# TC37X register map
File version: 1.0.0
CPU: CM4 r0p1, little endian, MPU, FPU, VTOR, 3 interrupt priority bits
Registers are 16-bit, read-write, reset 0x0 unless marked. A register's access mark holds for its fields unless they carry their own. Offsets are from the block's base; [hi:lo] are bit positions; {n}, {i} and the like mark numbered series.

## INT — ce_int
Base 0xF0037000
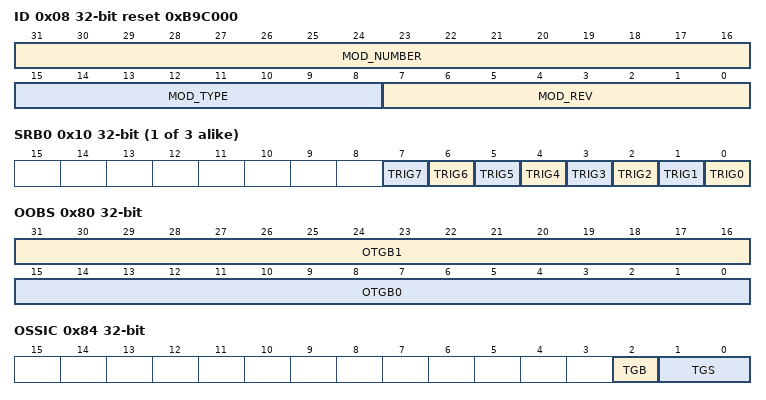
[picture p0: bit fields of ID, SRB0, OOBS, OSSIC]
0x08 ID 32-bit ro reset 0xB9C000 (reset mask 0xFFFFFF00) — Module Identification Register
  [31:16] MOD_NUMBER — Module Number Value
  [15:8] MOD_TYPE — Module Type
  [7:0] MOD_REV — Module Revision Number
{0x10+4i} SRB{i} 32-bit wo (i=0..2) — Service Request Broadcast Register {i}
  [n] TRIG{n} (n=0..7) — General Purpose Service Request Trigger {n}
0x80 OOBS 32-bit ro — OTGM OTGB0/1 Status
  [31:16] OTGB1 — Status of OTGB1
  [15:0] OTGB0 — Status of OTGB0
0x84 OSSIC 32-bit — OTGM SSI Control
  [2] TGB — OTGB0/1 Bus Select
  [1:0] TGS — Trigger Set for OTGB0/1
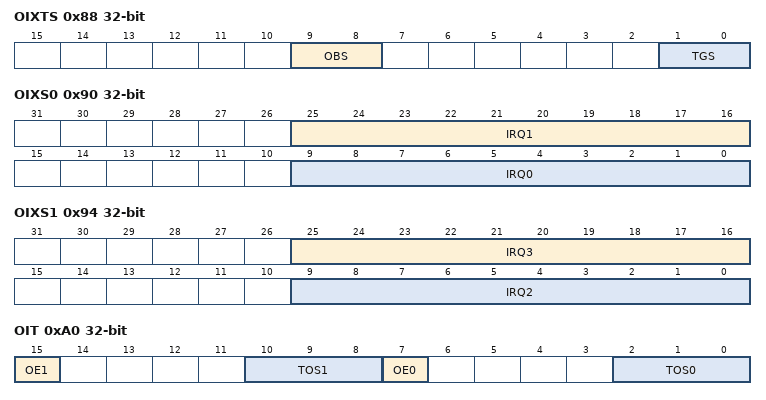
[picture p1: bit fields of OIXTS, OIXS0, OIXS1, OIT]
0x88 OIXTS 32-bit — OTGM IRQ MUX Trigger Set Select
  [9:8] OBS — Overlay Byte Select
  [1:0] TGS — Trigger Set Select for OTGB0/1 Overlay
0x8C OIXMS 32-bit — OTGM IRQ MUX Missed IRQ Select
  [9:0] MIRQ — SRN Index for Missed Interrupt Trigger
0x90 OIXS0 32-bit — OTGM IRQ MUX Select 0
  [25:16] IRQ1 — SRN Index for Interrupt Trigger 1
  [9:0] IRQ0 — SRN Index for Interrupt Trigger 0
0x94 OIXS1 32-bit — OTGM IRQ MUX Select 1
  [25:16] IRQ3 — SRN Index for Interrupt Trigger 3
  [9:0] IRQ2 — SRN Index for Interrupt Trigger 2
0xA0 OIT 32-bit — OTGM IRQ Trace
  [15] OE1 — Output Enable for OTGB1
  [10:8] TOS1 — Type of Service for Observation on OTGB1
  [7] OE0 — Output Enable for OTGB0
  [2:0] TOS0 — Type of Service for Observation on OTGB0
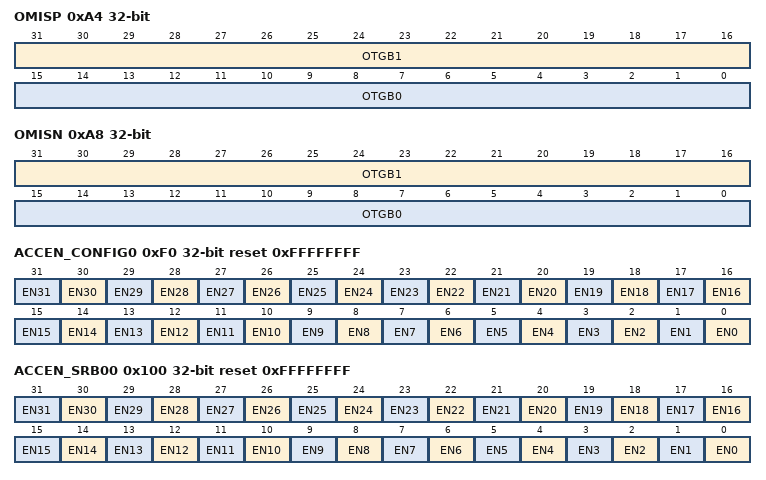
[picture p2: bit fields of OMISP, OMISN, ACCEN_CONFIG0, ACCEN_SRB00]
0xA4 OMISP 32-bit — OTGM MCDS I/F Sensitivity Posedge
  [31:16] OTGB1 — Bitwise Posedge Sensitivity for OTGB1
  [15:0] OTGB0 — Bitwise Posedge Sensitivity for OTGB0
0xA8 OMISN 32-bit — OTGM MCDS I/F Sensitivity Negedge
  [31:16] OTGB1 — Bitwise Negedge Sensitivity for OTGB1
  [15:0] OTGB0 — Bitwise Negedge Sensitivity for OTGB0
0xF0 ACCEN_CONFIG0 32-bit reset 0xFFFFFFFF — Access Enable covering all INT_ECRx and all SRCy[15:0], Register 0
  [n] EN{n} (n=0..31) — Access Enable for Master TAG ID {n} - EN{n}
0xF4 ACCEN_CONFIG1 32-bit ro — Access Enable covering all INT_ECRx and all SRCy[15:0], Register 1
0x100 ACCEN_SRB00 32-bit reset 0xFFFFFFFF — Access Enable covering SRB0, Register 0
  [n] EN{n} (n=0..31) — Access Enable for Master TAG ID {n}
0x104 ACCEN_SRB01 32-bit ro — Access Enable covering SRB0, Register 1
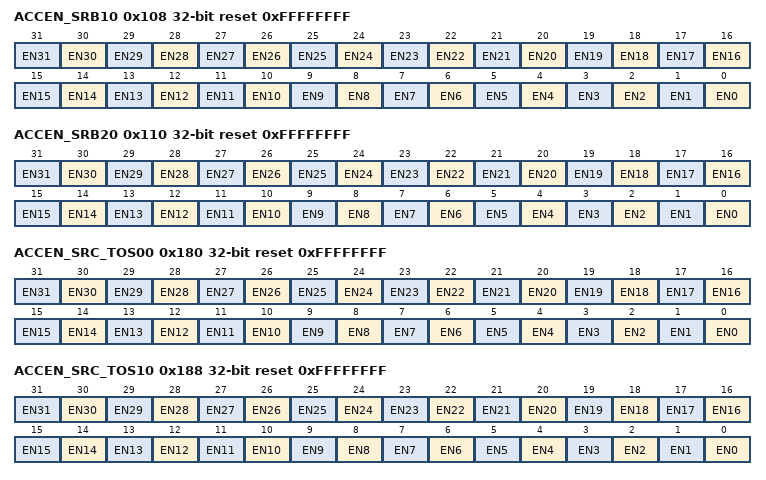
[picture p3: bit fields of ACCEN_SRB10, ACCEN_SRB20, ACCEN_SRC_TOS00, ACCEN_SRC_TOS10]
0x108 ACCEN_SRB10 32-bit reset 0xFFFFFFFF — Access Enable covering SRB1, Register 0
  [n] EN{n} (n=0..31) — Access Enable for Master TAG ID {n}
0x10C ACCEN_SRB11 32-bit ro — Access Enable covering SRB1, Register 1
0x110 ACCEN_SRB20 32-bit reset 0xFFFFFFFF — Access Enable covering SRB2, Register 0
  [n] EN{n} (n=0..31) — Access Enable for Master TAG ID {n}
0x114 ACCEN_SRB21 32-bit ro — Access Enable covering SRB2, Register 1
0x180 ACCEN_SRC_TOS00 32-bit reset 0xFFFFFFFF — Access Enable covering all SRCx[31:16] mapped to ICU0, Register 0
  [n] EN{n} (n=0..31) — Access Enable for Master TAG ID {n}
0x184 ACCEN_SRC_TOS01 32-bit ro — Access Enable covering all SRCx[31:16] mapped to ICU0, Register 1
0x188 ACCEN_SRC_TOS10 32-bit reset 0xFFFFFFFF — Access Enable covering all SRCx[31:16] mapped to ICU1, Register 0
  [n] EN{n} (n=0..31) — Access Enable for Master TAG ID {n}
0x18C ACCEN_SRC_TOS11 32-bit ro — Access Enable covering all SRCx[31:16] mapped to ICU1, Register 1
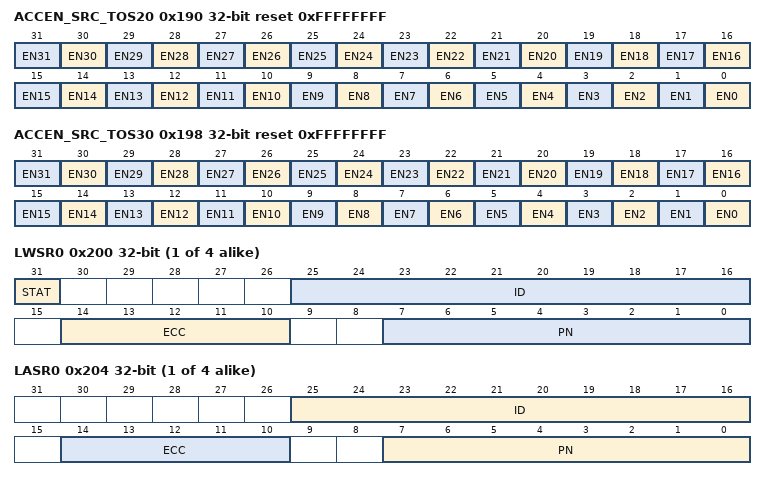
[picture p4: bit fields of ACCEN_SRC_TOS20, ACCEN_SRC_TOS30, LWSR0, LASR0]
0x190 ACCEN_SRC_TOS20 32-bit reset 0xFFFFFFFF — Access Enable covering all SRCx[31:16] mapped to ICU2, Register 0
  [n] EN{n} (n=0..31) — Access Enable for Master TAG ID {n}
0x194 ACCEN_SRC_TOS21 32-bit ro — Access Enable covering all SRCx[31:16] mapped to ICU2, Register 1
0x198 ACCEN_SRC_TOS30 32-bit reset 0xFFFFFFFF — Access Enable covering all SRCx[31:16] mapped to ICU3, Register 0
  [n] EN{n} (n=0..31) — Access Enable for Master TAG ID {n}
0x19C ACCEN_SRC_TOS31 32-bit ro — Access Enable covering all SRCx[31:16] mapped to ICU3, Register 1
{0x200+0x10*i} LWSR{i} 32-bit ro (i=0..3) — Latest Winning Service Request Register {i}, related to ICU{i}
  [31] STAT — LWSR Register Status
  [25:16] ID — Latest Winner Index Number
  [14:10] ECC — Latest Winner ECC
  [7:0] PN — Latest Winner Priority Number
{0x204+0x10*i} LASR{i} 32-bit ro (i=0..3) — Last Acknowledged Service Request Register {i}, related to ICU{i}
  [25:16] ID — Last Acknowledged Interrupt SRN ID
  [14:10] ECC — Last Acknowledged Interrupt ECC
  [7:0] PN — Last Acknowledged Service Request Priority Number
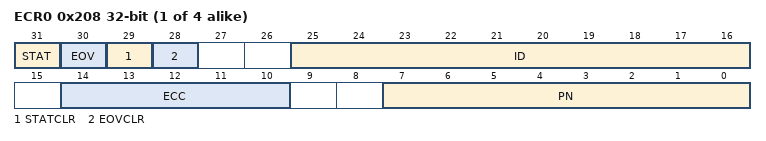
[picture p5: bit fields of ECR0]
{0x208+0x10*i} ECR{i} 32-bit (i=0..3) — Error Capture Register {i}, related to ICU{i}
  [31] STAT ro — Error Status Bit
  [30] EOV ro — Error Overflow Bit
  [29] STATCLR wo — Error Status Bit
  [28] EOVCLR wo — Error Overflow Bit
  [25:16] ID — Service Request Node ID
  [14:10] ECC — Service Request ECC
  [7:0] PN — Service Request Priority Number
